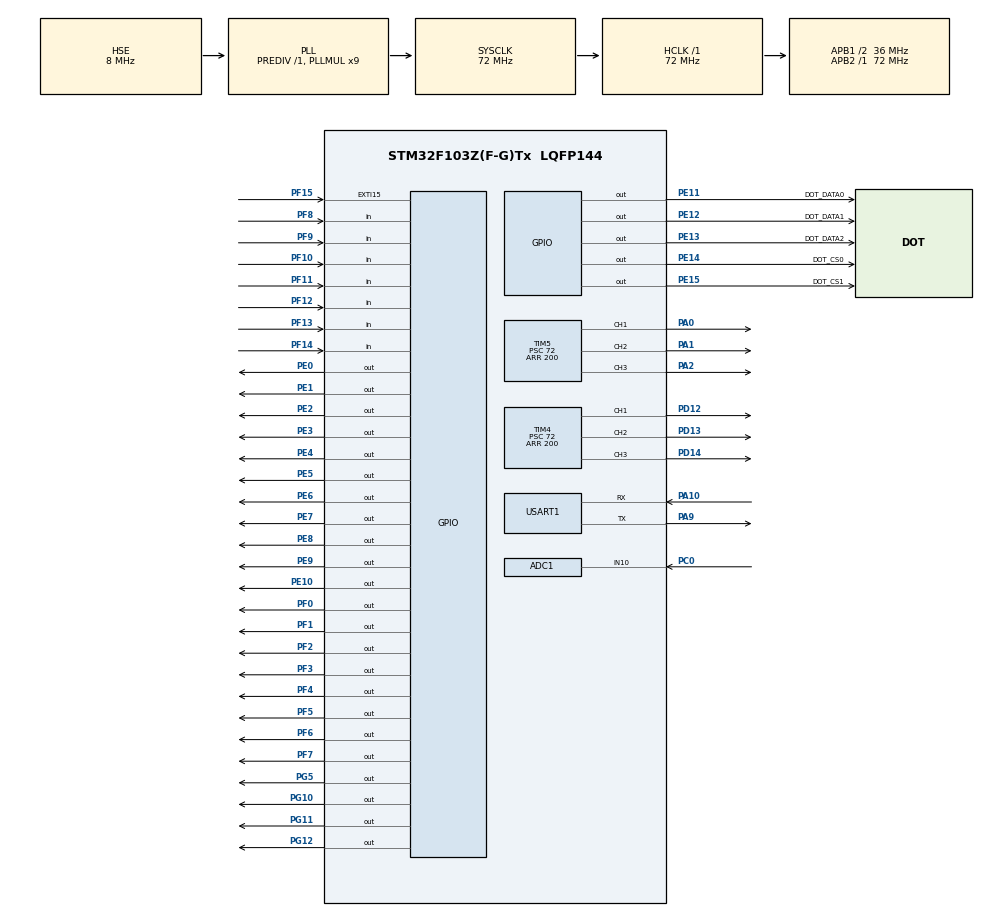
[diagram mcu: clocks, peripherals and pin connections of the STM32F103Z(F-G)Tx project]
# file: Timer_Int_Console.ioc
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ADC1.Channel-0\#ChannelRegularConversion=ADC_CHANNEL_10
ADC1.NbrOfConversionFlag=1
ADC1.Rank-0\#ChannelRegularConversion=1
ADC1.SamplingTime-0\#ChannelRegularConversion=ADC_SAMPLETIME_1CYCLE_5
ADC1.master=1
Mcu.Family=STM32F1
Mcu.Name=STM32F103Z(F-G)Tx
Mcu.Package=LQFP144
NVIC.EXTI15_10_IRQn=true\:0\:0\:false\:false\:true\:true\:true
NVIC.PriorityGroup=NVIC_PRIORITYGROUP_4
NVIC.TIM3_IRQn=true\:0\:0\:false\:false\:true\:true\:true
NVIC.USART1_IRQn=true\:0\:0\:false\:false\:true\:true\:true
OSC_IN.Mode=HSE-External-Oscillator
OSC_IN.Signal=RCC_OSC_IN
OSC_OUT.Mode=HSE-External-Oscillator
OSC_OUT.Signal=RCC_OSC_OUT
PA0-WKUP.Signal=S_TIM5_CH1
PA1.Signal=S_TIM5_CH2
PA10.Mode=Asynchronous
PA10.Signal=USART1_RX
PA13.Mode=Serial_Wire
PA13.Signal=SYS_JTMS-SWDIO
PA14.Mode=Serial_Wire
PA14.Signal=SYS_JTCK-SWCLK
PA2.Signal=S_TIM5_CH3
PA9.Mode=Asynchronous
PA9.Signal=USART1_TX
PC0.Signal=ADCx_IN10
PD12.Signal=S_TIM4_CH1
PD13.Signal=S_TIM4_CH2
PD14.Signal=S_TIM4_CH3
PE0.Signal=GPIO_Output
PE1.Signal=GPIO_Output
PE10.Signal=GPIO_Output
PE11.GPIO_Label=DOT_DATA0
PE11.Signal=GPIO_Output
PE12.GPIO_Label=DOT_DATA1
PE12.Signal=GPIO_Output
PE13.GPIO_Label=DOT_DATA2
PE13.Signal=GPIO_Output
PE14.GPIO_Label=DOT_CS0
PE14.Signal=GPIO_Output
PE15.GPIO_Label=DOT_CS1
PE15.Signal=GPIO_Output
PE2.Signal=GPIO_Output
PE3.Signal=GPIO_Output
PE4.Signal=GPIO_Output
PE5.Signal=GPIO_Output
PE6.Signal=GPIO_Output
PE7.Signal=GPIO_Output
PE8.Signal=GPIO_Output
PE9.Signal=GPIO_Output
PF0.Signal=GPIO_Output
PF1.Signal=GPIO_Output
PF10.Signal=GPIO_Input
PF11.Signal=GPIO_Input
PF12.Signal=GPIO_Input
PF13.Signal=GPIO_Input
PF14.Signal=GPIO_Input
PF15.GPIO_ModeDefaultEXTI=GPIO_MODE_IT_RISING
PF15.Signal=GPXTI15
PF2.Signal=GPIO_Output
PF3.Signal=GPIO_Output
PF4.Signal=GPIO_Output
PF5.Signal=GPIO_Output
PF6.Signal=GPIO_Output
PF7.Signal=GPIO_Output
PF8.Signal=GPIO_Input
PF9.Signal=GPIO_Input
PG10.Signal=GPIO_Output
PG11.Signal=GPIO_Output
PG12.Signal=GPIO_Output
PG5.Signal=GPIO_Output
ProjectManager.HeapSize=0x200
ProjectManager.StackSize=0x400
ProjectManager.TargetToolchain=MDK-ARM V5.27
RCC.ADCPresc=RCC_ADCPCLK2_DIV6
RCC.AHBFreq_Value=72000000
RCC.APB1CLKDivider=RCC_HCLK_DIV2
RCC.APB1Freq_Value=36000000
RCC.APB1TimFreq_Value=72000000
RCC.APB2Freq_Value=72000000
RCC.APB2TimFreq_Value=72000000
RCC.HCLKFreq_Value=72000000
RCC.PLLMUL=RCC_PLL_MUL9
RCC.PLLSourceVirtual=RCC_PLLSOURCE_HSE
RCC.SYSCLKFreq_VALUE=72000000
RCC.SYSCLKSource=RCC_SYSCLKSOURCE_PLLCLK
RCC.USBFreq_Value=72000000
SH.ADCx_IN10.0=ADC1_IN10,IN10
SH.S_TIM4_CH1.0=TIM4_CH1,PWM Generation1 CH1
SH.S_TIM4_CH2.0=TIM4_CH2,PWM Generation2 CH2
SH.S_TIM4_CH3.0=TIM4_CH3,PWM Generation3 CH3
SH.S_TIM5_CH1.0=TIM5_CH1,PWM Generation1 CH1
SH.S_TIM5_CH2.0=TIM5_CH2,PWM Generation2 CH2
SH.S_TIM5_CH3.0=TIM5_CH3,PWM Generation3 CH3
TIM3.AutoReloadPreload=TIM_AUTORELOAD_PRELOAD_DISABLE
TIM3.Period=50000
TIM3.Prescaler=720
TIM4.Channel-PWM\ Generation1\ CH1=TIM_CHANNEL_1
TIM4.Channel-PWM\ Generation2\ CH2=TIM_CHANNEL_2
TIM4.Channel-PWM\ Generation3\ CH3=TIM_CHANNEL_3
TIM4.Period=200
TIM4.Prescaler=72
TIM5.Channel-PWM\ Generation1\ CH1=TIM_CHANNEL_1
TIM5.Channel-PWM\ Generation2\ CH2=TIM_CHANNEL_2
TIM5.Channel-PWM\ Generation3\ CH3=TIM_CHANNEL_3
TIM5.Period=200
TIM5.Prescaler=72
USART1.VirtualMode=VM_ASYNC
VP_TIM3_VS_ClockSourceINT.Mode=Internal
board=custom

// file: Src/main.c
/* USER CODE BEGIN Header */
/**
  ******************************************************************************
  * @file           : main.c
  * @brief          : Main program body
  ******************************************************************************
  * @attention
  *
  * <h2><center>&copy; Copyright (c) 2021 STMicroelectronics.
  * All rights reserved.</center></h2>
  *
  * This software component is licensed by ST under BSD 3-Clause license,
  * the "License"; You may not use this file except in compliance with the
  * License. You may obtain a copy of the License at:
  *                        opensource.org/licenses/BSD-3-Clause
  *
  ******************************************************************************
  */
/* USER CODE END Header */
#include "main.h"
#include <stdio.h>
#include "cmdline.h"
#include "cmd_func.h"
#include "Serial.h"

ADC_HandleTypeDef hadc1;

TIM_HandleTypeDef htim3;
TIM_HandleTypeDef htim4;
TIM_HandleTypeDef htim5;

UART_HandleTypeDef huart1;

void SystemClock_Config(void);
static void MX_GPIO_Init(void);
static void MX_TIM3_Init(void);
static void MX_USART1_UART_Init(void);
static void MX_ADC1_Init(void);
static void MX_TIM4_Init(void);
static void MX_TIM5_Init(void);

int main(void)
{
	int nStatus;

  HAL_Init();
  SystemClock_Config();

  MX_GPIO_Init();
  MX_TIM3_Init();
  MX_USART1_UART_Init();
  MX_ADC1_Init();
  MX_TIM4_Init();
  MX_TIM5_Init();

	HAL_TIM_Base_Start_IT(&htim3);

	printf("\n\r UART Printf Example: retarget the C library printf function to the UART\n\r");
	printf("\n\r DATA : %s , LINE : %d\n\r",__DATE__,__LINE__);

  while (1)
  {

				//
        // Print a prompt to the console.  Show the CWD.
        //
        printf("cmd> ");

        //
        // Get a line of text from the user.
        //
        UARTgets(g_pcCmdBuf, sizeof(g_pcCmdBuf));

        //
        // Pass the line from the user to the command processor.  It will be
        // parsed and valid commands executed.
        //
        nStatus = CmdLineProcess(g_pcCmdBuf);

        //
        // Handle the case of bad command.
        //
        if(nStatus == CMDLINE_BAD_CMD)
        {
            printf("Bad command!\n\r");
        }

        //
        // Handle the case of too many arguments.
        //
        else if(nStatus == CMDLINE_TOO_MANY_ARGS)
        {
            printf("Too many arguments for command processor!\n\r");
        }

        //
        // Otherwise the command was executed.  Print the error code if one was
        // returned.
        //
        else if(nStatus != 0)
        {
            //printf("Command returned error code \n");
        }

  }

}

void SystemClock_Config(void)
{
  RCC_OscInitTypeDef RCC_OscInitStruct = {0};
  RCC_ClkInitTypeDef RCC_ClkInitStruct = {0};
  RCC_PeriphCLKInitTypeDef PeriphClkInit = {0};

  /** Initializes the RCC Oscillators according to the specified parameters
  * in the RCC_OscInitTypeDef structure.
  */
  RCC_OscInitStruct.OscillatorType = RCC_OSCILLATORTYPE_HSE;
  RCC_OscInitStruct.HSEState = RCC_HSE_ON;
  RCC_OscInitStruct.HSEPredivValue = RCC_HSE_PREDIV_DIV1;
  RCC_OscInitStruct.HSIState = RCC_HSI_ON;
  RCC_OscInitStruct.PLL.PLLState = RCC_PLL_ON;
  RCC_OscInitStruct.PLL.PLLSource = RCC_PLLSOURCE_HSE;
  RCC_OscInitStruct.PLL.PLLMUL = RCC_PLL_MUL9;
  if (HAL_RCC_OscConfig(&RCC_OscInitStruct) != HAL_OK)
  {
    Error_Handler();
  }
  /** Initializes the CPU, AHB and APB buses clocks
  */
  RCC_ClkInitStruct.ClockType = RCC_CLOCKTYPE_HCLK|RCC_CLOCKTYPE_SYSCLK
                              |RCC_CLOCKTYPE_PCLK1|RCC_CLOCKTYPE_PCLK2;
  RCC_ClkInitStruct.SYSCLKSource = RCC_SYSCLKSOURCE_PLLCLK;
  RCC_ClkInitStruct.AHBCLKDivider = RCC_SYSCLK_DIV1;
  RCC_ClkInitStruct.APB1CLKDivider = RCC_HCLK_DIV2;
  RCC_ClkInitStruct.APB2CLKDivider = RCC_HCLK_DIV1;

  if (HAL_RCC_ClockConfig(&RCC_ClkInitStruct, FLASH_LATENCY_2) != HAL_OK)
  {
    Error_Handler();
  }
  PeriphClkInit.PeriphClockSelection = RCC_PERIPHCLK_ADC;
  PeriphClkInit.AdcClockSelection = RCC_ADCPCLK2_DIV6;
  if (HAL_RCCEx_PeriphCLKConfig(&PeriphClkInit) != HAL_OK)
  {
    Error_Handler();
  }
}

static void MX_ADC1_Init(void)
{

  ADC_ChannelConfTypeDef sConfig = {0};

  /** Common config
  */
  hadc1.Instance = ADC1;
  hadc1.Init.ScanConvMode = ADC_SCAN_DISABLE;
  hadc1.Init.ContinuousConvMode = DISABLE;
  hadc1.Init.DiscontinuousConvMode = DISABLE;
  hadc1.Init.ExternalTrigConv = ADC_SOFTWARE_START;
  hadc1.Init.DataAlign = ADC_DATAALIGN_RIGHT;
  hadc1.Init.NbrOfConversion = 1;
  if (HAL_ADC_Init(&hadc1) != HAL_OK)
  {
    Error_Handler();
  }
  /** Configure Regular Channel
  */
  sConfig.Channel = ADC_CHANNEL_10;
  sConfig.Rank = ADC_REGULAR_RANK_1;
  sConfig.SamplingTime = ADC_SAMPLETIME_1CYCLE_5;
  if (HAL_ADC_ConfigChannel(&hadc1, &sConfig) != HAL_OK)
  {
    Error_Handler();
  }

}

static void MX_TIM3_Init(void)
{

  TIM_ClockConfigTypeDef sClockSourceConfig = {0};
  TIM_MasterConfigTypeDef sMasterConfig = {0};

  htim3.Instance = TIM3;
  htim3.Init.Prescaler = 720;
  htim3.Init.CounterMode = TIM_COUNTERMODE_UP;
  htim3.Init.Period = 50000;
  htim3.Init.ClockDivision = TIM_CLOCKDIVISION_DIV1;
  htim3.Init.AutoReloadPreload = TIM_AUTORELOAD_PRELOAD_DISABLE;
  if (HAL_TIM_Base_Init(&htim3) != HAL_OK)
  {
    Error_Handler();
  }
  sClockSourceConfig.ClockSource = TIM_CLOCKSOURCE_INTERNAL;
  if (HAL_TIM_ConfigClockSource(&htim3, &sClockSourceConfig) != HAL_OK)
  {
    Error_Handler();
  }
  sMasterConfig.MasterOutputTrigger = TIM_TRGO_RESET;
  sMasterConfig.MasterSlaveMode = TIM_MASTERSLAVEMODE_DISABLE;
  if (HAL_TIMEx_MasterConfigSynchronization(&htim3, &sMasterConfig) != HAL_OK)
  {
    Error_Handler();
  }

}

static void MX_TIM4_Init(void)
{

  TIM_MasterConfigTypeDef sMasterConfig = {0};
  TIM_OC_InitTypeDef sConfigOC = {0};

  htim4.Instance = TIM4;
  htim4.Init.Prescaler = 72;
  htim4.Init.CounterMode = TIM_COUNTERMODE_UP;
  htim4.Init.Period = 200;
  htim4.Init.ClockDivision = TIM_CLOCKDIVISION_DIV1;
  htim4.Init.AutoReloadPreload = TIM_AUTORELOAD_PRELOAD_DISABLE;
  if (HAL_TIM_PWM_Init(&htim4) != HAL_OK)
  {
    Error_Handler();
  }
  sMasterConfig.MasterOutputTrigger = TIM_TRGO_RESET;
  sMasterConfig.MasterSlaveMode = TIM_MASTERSLAVEMODE_DISABLE;
  if (HAL_TIMEx_MasterConfigSynchronization(&htim4, &sMasterConfig) != HAL_OK)
  {
    Error_Handler();
  }
  sConfigOC.OCMode = TIM_OCMODE_PWM1;
  sConfigOC.Pulse = 0;
  sConfigOC.OCPolarity = TIM_OCPOLARITY_HIGH;
  sConfigOC.OCFastMode = TIM_OCFAST_DISABLE;
  if (HAL_TIM_PWM_ConfigChannel(&htim4, &sConfigOC, TIM_CHANNEL_1) != HAL_OK)
  {
    Error_Handler();
  }
  if (HAL_TIM_PWM_ConfigChannel(&htim4, &sConfigOC, TIM_CHANNEL_2) != HAL_OK)
  {
    Error_Handler();
  }
  if (HAL_TIM_PWM_ConfigChannel(&htim4, &sConfigOC, TIM_CHANNEL_3) != HAL_OK)
  {
    Error_Handler();
  }

  HAL_TIM_MspPostInit(&htim4);

}

static void MX_TIM5_Init(void)
{

  TIM_MasterConfigTypeDef sMasterConfig = {0};
  TIM_OC_InitTypeDef sConfigOC = {0};

  htim5.Instance = TIM5;
  htim5.Init.Prescaler = 72;
  htim5.Init.CounterMode = TIM_COUNTERMODE_UP;
  htim5.Init.Period = 200;
  htim5.Init.ClockDivision = TIM_CLOCKDIVISION_DIV1;
  htim5.Init.AutoReloadPreload = TIM_AUTORELOAD_PRELOAD_DISABLE;
  if (HAL_TIM_PWM_Init(&htim5) != HAL_OK)
  {
    Error_Handler();
  }
  sMasterConfig.MasterOutputTrigger = TIM_TRGO_RESET;
  sMasterConfig.MasterSlaveMode = TIM_MASTERSLAVEMODE_DISABLE;
  if (HAL_TIMEx_MasterConfigSynchronization(&htim5, &sMasterConfig) != HAL_OK)
  {
    Error_Handler();
  }
  sConfigOC.OCMode = TIM_OCMODE_PWM1;
  sConfigOC.Pulse = 0;
  sConfigOC.OCPolarity = TIM_OCPOLARITY_HIGH;
  sConfigOC.OCFastMode = TIM_OCFAST_DISABLE;
  if (HAL_TIM_PWM_ConfigChannel(&htim5, &sConfigOC, TIM_CHANNEL_1) != HAL_OK)
  {
    Error_Handler();
  }
  if (HAL_TIM_PWM_ConfigChannel(&htim5, &sConfigOC, TIM_CHANNEL_2) != HAL_OK)
  {
    Error_Handler();
  }
  if (HAL_TIM_PWM_ConfigChannel(&htim5, &sConfigOC, TIM_CHANNEL_3) != HAL_OK)
  {
    Error_Handler();
  }

  HAL_TIM_MspPostInit(&htim5);

}

static void MX_USART1_UART_Init(void)
{

  huart1.Instance = USART1;
  huart1.Init.BaudRate = 115200;
  huart1.Init.WordLength = UART_WORDLENGTH_8B;
  huart1.Init.StopBits = UART_STOPBITS_1;
  huart1.Init.Parity = UART_PARITY_NONE;
  huart1.Init.Mode = UART_MODE_TX_RX;
  huart1.Init.HwFlowCtl = UART_HWCONTROL_NONE;
  huart1.Init.OverSampling = UART_OVERSAMPLING_16;
  if (HAL_UART_Init(&huart1) != HAL_OK)
  {
    Error_Handler();
  }

}

static void MX_GPIO_Init(void)
{
  GPIO_InitTypeDef GPIO_InitStruct = {0};

  /* GPIO Ports Clock Enable */
  __HAL_RCC_GPIOE_CLK_ENABLE();
  __HAL_RCC_GPIOF_CLK_ENABLE();
  __HAL_RCC_GPIOC_CLK_ENABLE();
  __HAL_RCC_GPIOA_CLK_ENABLE();
  __HAL_RCC_GPIOD_CLK_ENABLE();
  __HAL_RCC_GPIOG_CLK_ENABLE();

  /*Configure GPIO pin Output Level */
  HAL_GPIO_WritePin(GPIOE, GPIO_PIN_2|GPIO_PIN_3|GPIO_PIN_4|GPIO_PIN_5
                          |GPIO_PIN_6|GPIO_PIN_7|GPIO_PIN_8|GPIO_PIN_9
                          |GPIO_PIN_10|DOT_DATA0_Pin|DOT_DATA1_Pin|DOT_DATA2_Pin
                          |DOT_CS0_Pin|DOT_CS1_Pin|GPIO_PIN_0|GPIO_PIN_1, GPIO_PIN_RESET);

  /*Configure GPIO pin Output Level */
  HAL_GPIO_WritePin(GPIOF, GPIO_PIN_0|GPIO_PIN_1|GPIO_PIN_2|GPIO_PIN_3
                          |GPIO_PIN_4|GPIO_PIN_5|GPIO_PIN_6|GPIO_PIN_7, GPIO_PIN_RESET);

  /*Configure GPIO pin Output Level */
  HAL_GPIO_WritePin(GPIOG, GPIO_PIN_5|GPIO_PIN_10|GPIO_PIN_11|GPIO_PIN_12, GPIO_PIN_RESET);

  /*Configure GPIO pins : PE2 PE3 PE4 PE5
                           PE6 PE7 PE8 PE9
                           PE10 DOT_DATA0_Pin DOT_DATA1_Pin DOT_DATA2_Pin
                           DOT_CS0_Pin DOT_CS1_Pin PE0 PE1 */
  GPIO_InitStruct.Pin = GPIO_PIN_2|GPIO_PIN_3|GPIO_PIN_4|GPIO_PIN_5
                          |GPIO_PIN_6|GPIO_PIN_7|GPIO_PIN_8|GPIO_PIN_9
                          |GPIO_PIN_10|DOT_DATA0_Pin|DOT_DATA1_Pin|DOT_DATA2_Pin
                          |DOT_CS0_Pin|DOT_CS1_Pin|GPIO_PIN_0|GPIO_PIN_1;
  GPIO_InitStruct.Mode = GPIO_MODE_OUTPUT_PP;
  GPIO_InitStruct.Pull = GPIO_NOPULL;
  GPIO_InitStruct.Speed = GPIO_SPEED_FREQ_LOW;
  HAL_GPIO_Init(GPIOE, &GPIO_InitStruct);

  /*Configure GPIO pins : PF0 PF1 PF2 PF3
                           PF4 PF5 PF6 PF7 */
  GPIO_InitStruct.Pin = GPIO_PIN_0|GPIO_PIN_1|GPIO_PIN_2|GPIO_PIN_3
                          |GPIO_PIN_4|GPIO_PIN_5|GPIO_PIN_6|GPIO_PIN_7;
  GPIO_InitStruct.Mode = GPIO_MODE_OUTPUT_PP;
  GPIO_InitStruct.Pull = GPIO_NOPULL;
  GPIO_InitStruct.Speed = GPIO_SPEED_FREQ_LOW;
  HAL_GPIO_Init(GPIOF, &GPIO_InitStruct);

  /*Configure GPIO pins : PF8 PF9 PF10 PF11
                           PF12 PF13 PF14 */
  GPIO_InitStruct.Pin = GPIO_PIN_8|GPIO_PIN_9|GPIO_PIN_10|GPIO_PIN_11
                          |GPIO_PIN_12|GPIO_PIN_13|GPIO_PIN_14;
  GPIO_InitStruct.Mode = GPIO_MODE_INPUT;
  GPIO_InitStruct.Pull = GPIO_NOPULL;
  HAL_GPIO_Init(GPIOF, &GPIO_InitStruct);

  /*Configure GPIO pin : PF15 */
  GPIO_InitStruct.Pin = GPIO_PIN_15;
  GPIO_InitStruct.Mode = GPIO_MODE_IT_RISING;
  GPIO_InitStruct.Pull = GPIO_NOPULL;
  HAL_GPIO_Init(GPIOF, &GPIO_InitStruct);

  /*Configure GPIO pins : PG5 PG10 PG11 PG12 */
  GPIO_InitStruct.Pin = GPIO_PIN_5|GPIO_PIN_10|GPIO_PIN_11|GPIO_PIN_12;
  GPIO_InitStruct.Mode = GPIO_MODE_OUTPUT_PP;
  GPIO_InitStruct.Pull = GPIO_NOPULL;
  GPIO_InitStruct.Speed = GPIO_SPEED_FREQ_LOW;
  HAL_GPIO_Init(GPIOG, &GPIO_InitStruct);

  /* EXTI interrupt init*/
  HAL_NVIC_SetPriority(EXTI15_10_IRQn, 0, 0);
  HAL_NVIC_EnableIRQ(EXTI15_10_IRQn);

}

/* USER CODE BEGIN 4 */
void HAL_TIM_PeriodElapsedCallback(TIM_HandleTypeDef *htim)
{
    if(htim->Instance == TIM3)
    {
          HAL_GPIO_TogglePin(GPIOF, GPIO_PIN_1);
			    //printf("\n\r LINE : %d  Timer Interrupt!!!\n\r",__LINE__);
    }
}

void HAL_GPIO_EXTI_Callback(uint16_t GPIO_Pin)
{
  if(GPIO_Pin == GPIO_PIN_15)
  {
         HAL_GPIO_TogglePin(GPIOF, GPIO_PIN_2);
		     //printf("\n\r LINE : %d  Ext Intterupt!!!\n\r",__LINE__);
  }

}
/* USER CODE END 4 */

void Error_Handler(void)
{
  __disable_irq();
  while (1)
  {
  }
}

/************************ (C) COPYRIGHT STMicroelectronics *****END OF FILE****/
